# M4K4A register map
File version: 0.1
Registers are 32-bit, read-write, reset 0x0 unless marked. A register's access mark holds for its fields unless they carry their own. Offsets are from the block's base; [hi:lo] are bit positions; {n}, {i} and the like mark numbered series.

## TSPI0 — Serial Interface (TSPI)
Base 0x40098000
Same registers: TSPI1 0x40099000, TSPI2 0x4009A000, TSPI3 0x4009B000
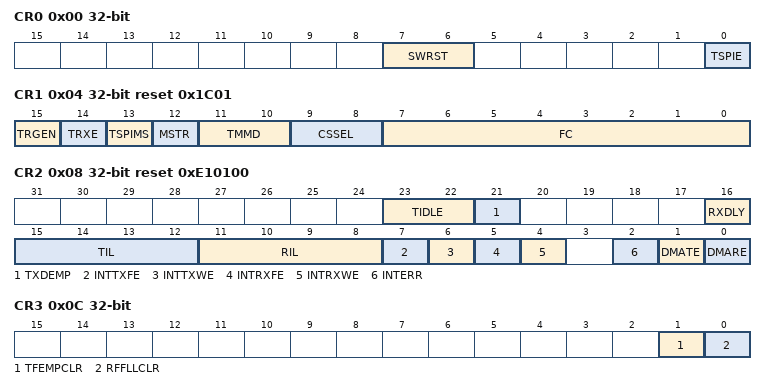
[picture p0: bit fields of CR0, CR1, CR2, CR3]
0x00 CR0 — TSPI Control Register 0
  [7:6] SWRST wo, [0] TSPIE
0x04 CR1 reset 0x1C01 — TSPI Control Register 1
  [15] TRGEN, [14] TRXE, [13] TSPIMS, [12] MSTR, [11:10] TMMD, [9:8] CSSEL, [7:0] FC
0x08 CR2 reset 0xE10100 — TSPI Control Register 2
  [23:22] TIDLE, [21] TXDEMP, [16] RXDLY, [15:12] TIL, [11:8] RIL, [7] INTTXFE, [6] INTTXWE, [5] INTRXFE, [4] INTRXWE, [2] INTERR, [1] DMATE, [0] DMARE
0x0C CR3 — TSPI Control Register 3
  [1] TFEMPCLR wo, [0] RFFLLCLR wo
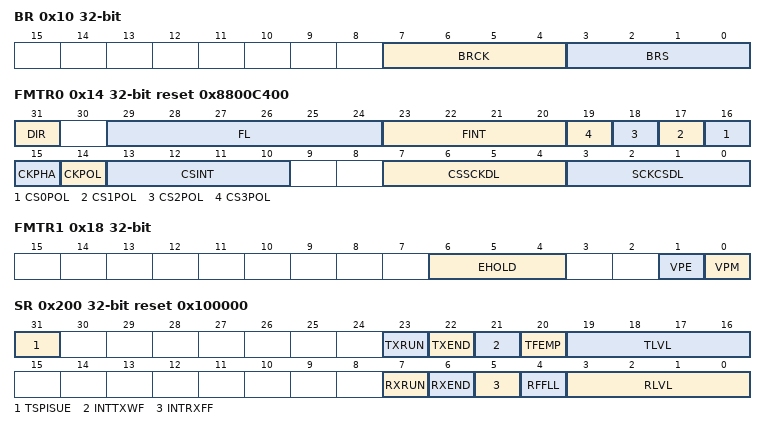
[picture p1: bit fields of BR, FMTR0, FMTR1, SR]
0x10 BR — TSPI Baud Rate Generator Control Register
  [7:4] BRCK, [3:0] BRS
0x14 FMTR0 reset 0x8800C400 — TSPI Format Control Register 0
  [31] DIR, [29:24] FL, [23:20] FINT, [n+16] CS{n}POL (n=0..3), [15] CKPHA, [14] CKPOL, [13:10] CSINT, [7:4] CSSCKDL, [3:0] SCKCSDL
0x18 FMTR1 — TSPI Format Control Register 1
  [6:4] EHOLD, [1] VPE, [0] VPM
0x100 DR — TSPI Data Register
  [31:0] TSPIDR
0x200 SR reset 0x100000 — TSPI Status Register
  [31] TSPISUE ro, [23] TXRUN ro, [22] TXEND, [21] INTTXWF, [20] TFEMP ro, [19:16] TLVL ro, [7] RXRUN ro, [6] RXEND, [5] INTRXFF, [4] RFFLL ro, [3:0] RLVL ro
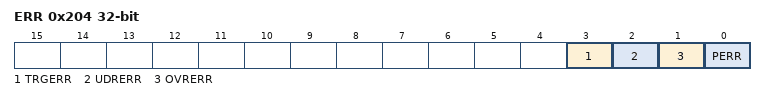
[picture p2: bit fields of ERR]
0x204 ERR — TSPI Parity Error Flag Register
  [3] TRGERR, [2] UDRERR, [1] OVRERR, [0] PERR

## I2C
Base 0x400A0000
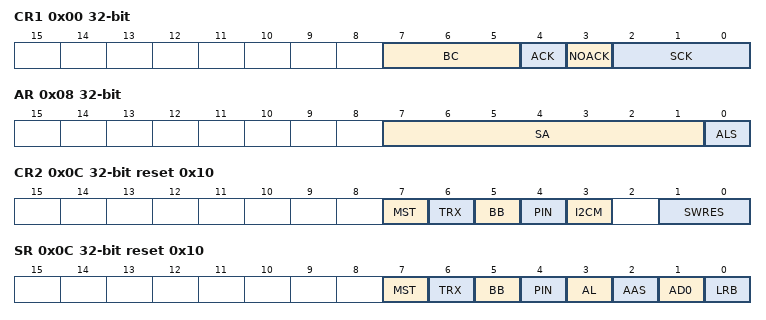
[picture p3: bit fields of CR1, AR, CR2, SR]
0x00 CR1 — I2C Control Register 1
  [7:5] BC, [4] ACK, [3] NOACK, [2:0] SCK
0x04 DBR — I2C Data Buffer Register
  [7:0] DB
0x08 AR — I2C Bus address Register
  [7:1] SA, [0] ALS
0x0C CR2 wo reset 0x10 — I2C Control Register 2
  [7] MST, [6] TRX, [5] BB, [4] PIN, [3] I2CM, [1:0] SWRES
0x0C SR ro reset 0x10 — I2C Status Register
  [7] MST, [6] TRX, [5] BB, [4] PIN, [3] AL, [2] AAS, [1] AD0, [0] LRB
0x10 PRS reset 0x1 — I2C Prescaler clcok setting Register
  [4:0] PRSCK
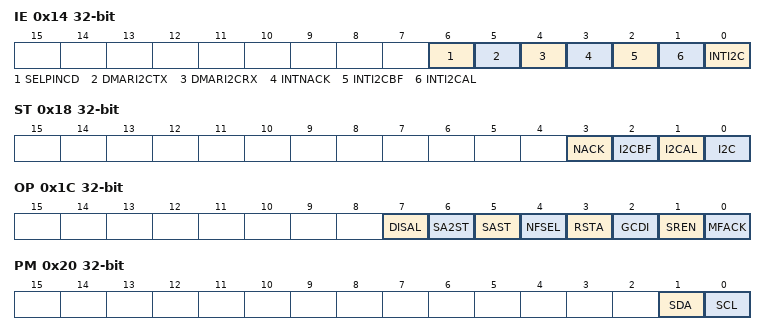
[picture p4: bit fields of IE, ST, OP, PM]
0x14 IE — I2C Interrupt Enable Register
  [6] SELPINCD, [5] DMARI2CTX, [4] DMARI2CRX, [3] INTNACK, [2] INTI2CBF, [1] INTI2CAL, [0] INTI2C
0x18 ST — I2C Interrupt Register
  [3] NACK, [2] I2CBF, [1] I2CAL, [0] I2C
0x1C OP — I2C Optiononal Function register
  [7] DISAL, [6] SA2ST ro, [5] SAST ro, [4] NFSEL, [3] RSTA, [2] GCDI, [1] SREN, [0] MFACK
0x20 PM ro — I2C Bus Monitor register
  [1] SDA, [0] SCL
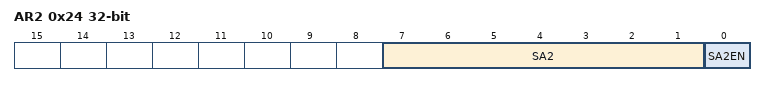
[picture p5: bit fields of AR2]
0x24 AR2 — I2C Second Slave address register
  [7:1] SA2, [0] SA2EN

## SH — Sampl-and-hold circuit
Base 0x400B8700
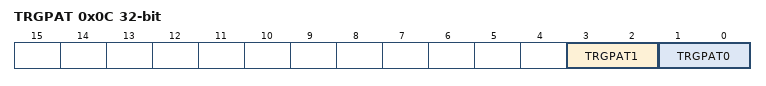
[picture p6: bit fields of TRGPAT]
0x0C TRGPAT — Trigger input switching control
  [3:2] TRGPAT1, [1:0] TRGPAT0

## AD — 12-bit ADC
Base 0x400B8800
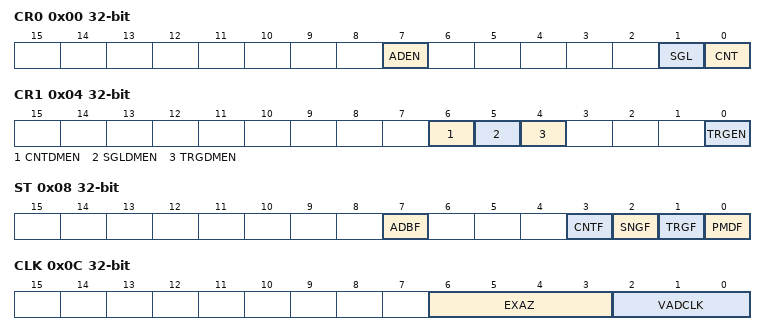
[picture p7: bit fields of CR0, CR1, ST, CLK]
0x00 CR0 — AD Control Register 0
  [7] ADEN, [1] SGL wo, [0] CNT
0x04 CR1 — AD Control Register 1
  [6] CNTDMEN, [5] SGLDMEN, [4] TRGDMEN, [0] TRGEN
0x08 ST ro — AD Status Register
  [7] ADBF, [3] CNTF, [2] SNGF, [1] TRGF, [0] PMDF
0x0C CLK — AD Conversion Clock Setting Register
  [6:3] EXAZ, [2:0] VADCLK
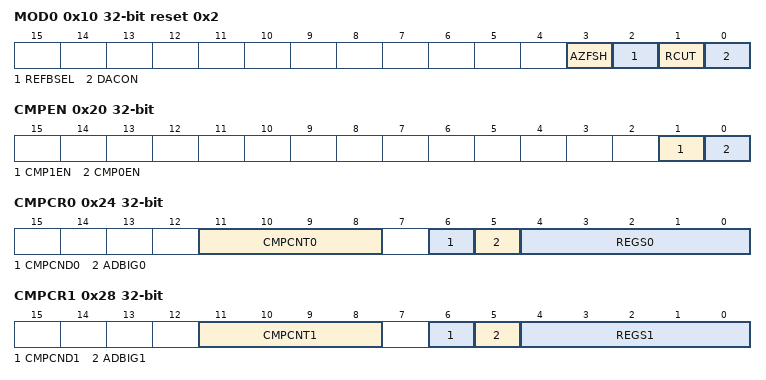
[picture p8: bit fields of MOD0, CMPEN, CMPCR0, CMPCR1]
0x10 MOD0 reset 0x2 — AD Mode Control Register 0
  [3] AZFSH, [2] REFBSEL, [1] RCUT, [0] DACON
0x14 MOD1 reset 0x304000 — AD Mode Control Register 1
0x18 MOD2 — AD Mode Control Register 2
0x20 CMPEN — AD Monitoring interrupt permission register
  [1] CMP1EN, [0] CMP0EN
0x24 CMPCR0 — AD Monitoring Setting Register 0
  [11:8] CMPCNT0, [6] CMPCND0, [5] ADBIG0, [4:0] REGS0
0x28 CMPCR1 — AD Monitoring Setting Register 1
  [11:8] CMPCNT1, [6] CMPCND1, [5] ADBIG1, [4:0] REGS1
0x2C CMP0 — AD Conversion Result Comparison Register 0
  [15:4] AD0CMP0
0x30 CMP1 — AD Conversion Result Comparison Register 1
  [15:4] AD0CMP1
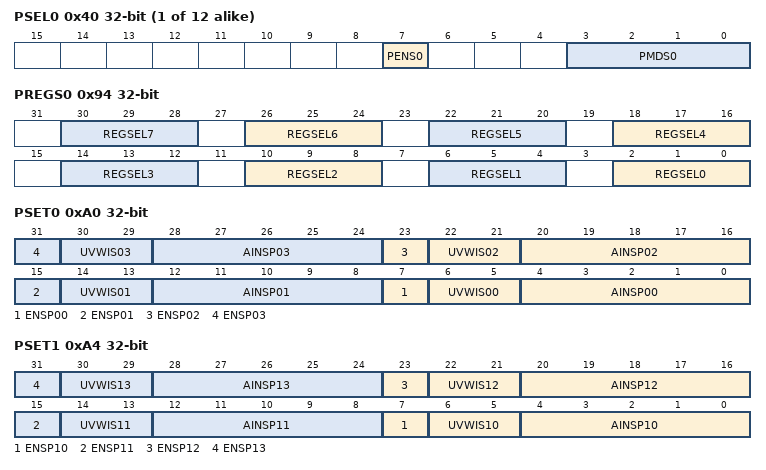
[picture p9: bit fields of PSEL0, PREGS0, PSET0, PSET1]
{0x40+4i} PSEL{i} (i=0..11) — AD PMD Trigger Program Number Select Register {i}
  [7] PENS{i}, [3:0] PMDS{i}
{0x70+4i} PINTS{i} (i=0..8) — AD PMD Trigger Interrupt Select Register {i}
  [2:0] INTSEL{i}
0x94 PREGS0 — AD PMD Trigger Conversion Result Storage Select Register 1
  [4n+2:4n] REGSEL{n} (n=0..7)
0x98 PREGS1 — AD PMD Trigger Conversion Result Storage Select Register 2
  [2:0] REGSEL8
0xA0 PSET0 — AD PMD Trigger Program Register 0
  [8n+7] ENSP{n:02} (n=0..3), [8n+6:8n+5] UVWIS{n:02} (n=0..3), [8n+4:8n] AINSP{n:02} (n=0..3)
0xA4 PSET1 — AD PMD Trigger Program Register 1
  [8n-73] ENSP{n} (n=10..13), [8n-74:8n-75] UVWIS{n} (n=10..13), [8n-76:8n-80] AINSP{n} (n=10..13)
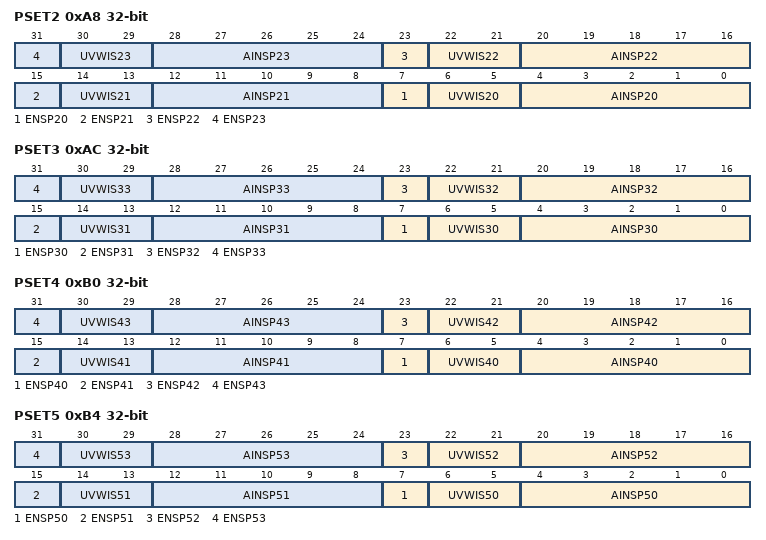
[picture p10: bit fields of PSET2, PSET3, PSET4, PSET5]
0xA8 PSET2 — AD PMD Trigger Program Register 2
  [8n-153] ENSP{n} (n=20..23), [8n-154:8n-155] UVWIS{n} (n=20..23), [8n-156:8n-160] AINSP{n} (n=20..23)
0xAC PSET3 — AD PMD Trigger Program Register 3
  [8n-233] ENSP{n} (n=30..33), [8n-234:8n-235] UVWIS{n} (n=30..33), [8n-236:8n-240] AINSP{n} (n=30..33)
0xB0 PSET4 — AD PMD Trigger Program Register 4
  [8n-313] ENSP{n} (n=40..43), [8n-314:8n-315] UVWIS{n} (n=40..43), [8n-316:8n-320] AINSP{n} (n=40..43)
0xB4 PSET5 — AD PMD Trigger Program Register 5
  [8n-393] ENSP{n} (n=50..53), [8n-394:8n-395] UVWIS{n} (n=50..53), [8n-396:8n-400] AINSP{n} (n=50..53)
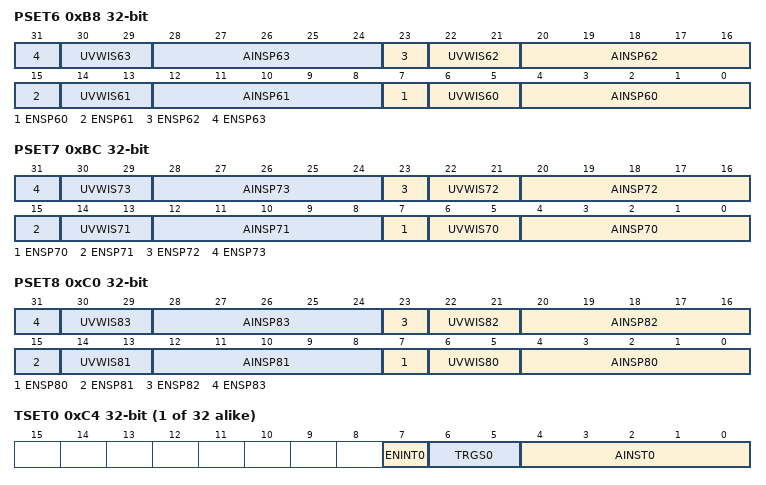
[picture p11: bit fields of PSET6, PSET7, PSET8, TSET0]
0xB8 PSET6 — AD PMD Trigger Program Register 6
  [8n-473] ENSP{n} (n=60..63), [8n-474:8n-475] UVWIS{n} (n=60..63), [8n-476:8n-480] AINSP{n} (n=60..63)
0xBC PSET7 — AD PMD Trigger Program Register 7
  [8n-553] ENSP{n} (n=70..73), [8n-554:8n-555] UVWIS{n} (n=70..73), [8n-556:8n-560] AINSP{n} (n=70..73)
0xC0 PSET8 — AD PMD Trigger Program Register 8
  [8n-633] ENSP{n} (n=80..83), [8n-634:8n-635] UVWIS{n} (n=80..83), [8n-636:8n-640] AINSP{n} (n=80..83)
{0xC4+4i} TSET{i} (i=0..31) — AD General purpose Trigger Program Register {i}
  [7] ENINT{i}, [6:5] TRGS{i}, [4:0] AINST{i}
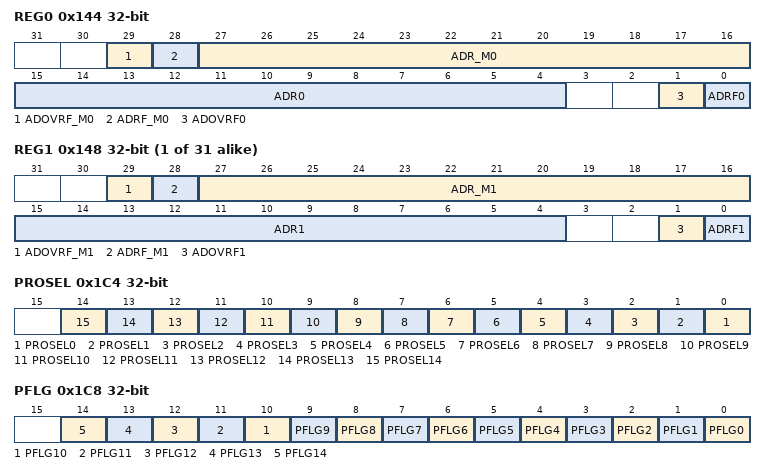
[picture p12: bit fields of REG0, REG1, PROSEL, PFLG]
0x144 REG0 ro — AD AD Conversion Result Register 0
  [29] ADOVRF_M0, [28] ADRF_M0, [27:16] ADR_M0, [15:4] ADR0, [1] ADOVRF0, [0] ADRF0
{0x144+4i} REG{i} ro (i=1..31) — AD Conversion Result Register {i}
  [29] ADOVRF_M{i}, [28] ADRF_M{i}, [27:16] ADR_M{i}, [15:4] ADR{i}, [1] ADOVRF{i}, [0] ADRF{i}
0x1C4 PROSEL — Conversion program resumed select register
  [n] PROSEL{n} (n=0..14)
0x1C8 PFLG ro — Priority determination state flag register
  [n] PFLG{n} (n=0..14)
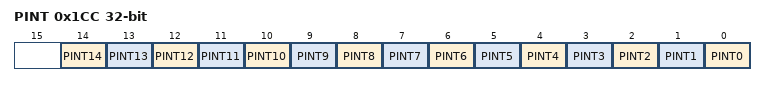
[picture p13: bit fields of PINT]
0x1CC PINT — Priority interrupt control register
  [n] PINT{n} (n=0..14)
